AUTOSAR XML (schema 4-3-0)
standard types defined: Boolean, UInt8, SInt8, UInt16, SInt16, UInt32, SInt32, boolean, uint8, sint8, uint16, sint16, uint32, sint32
package /Components
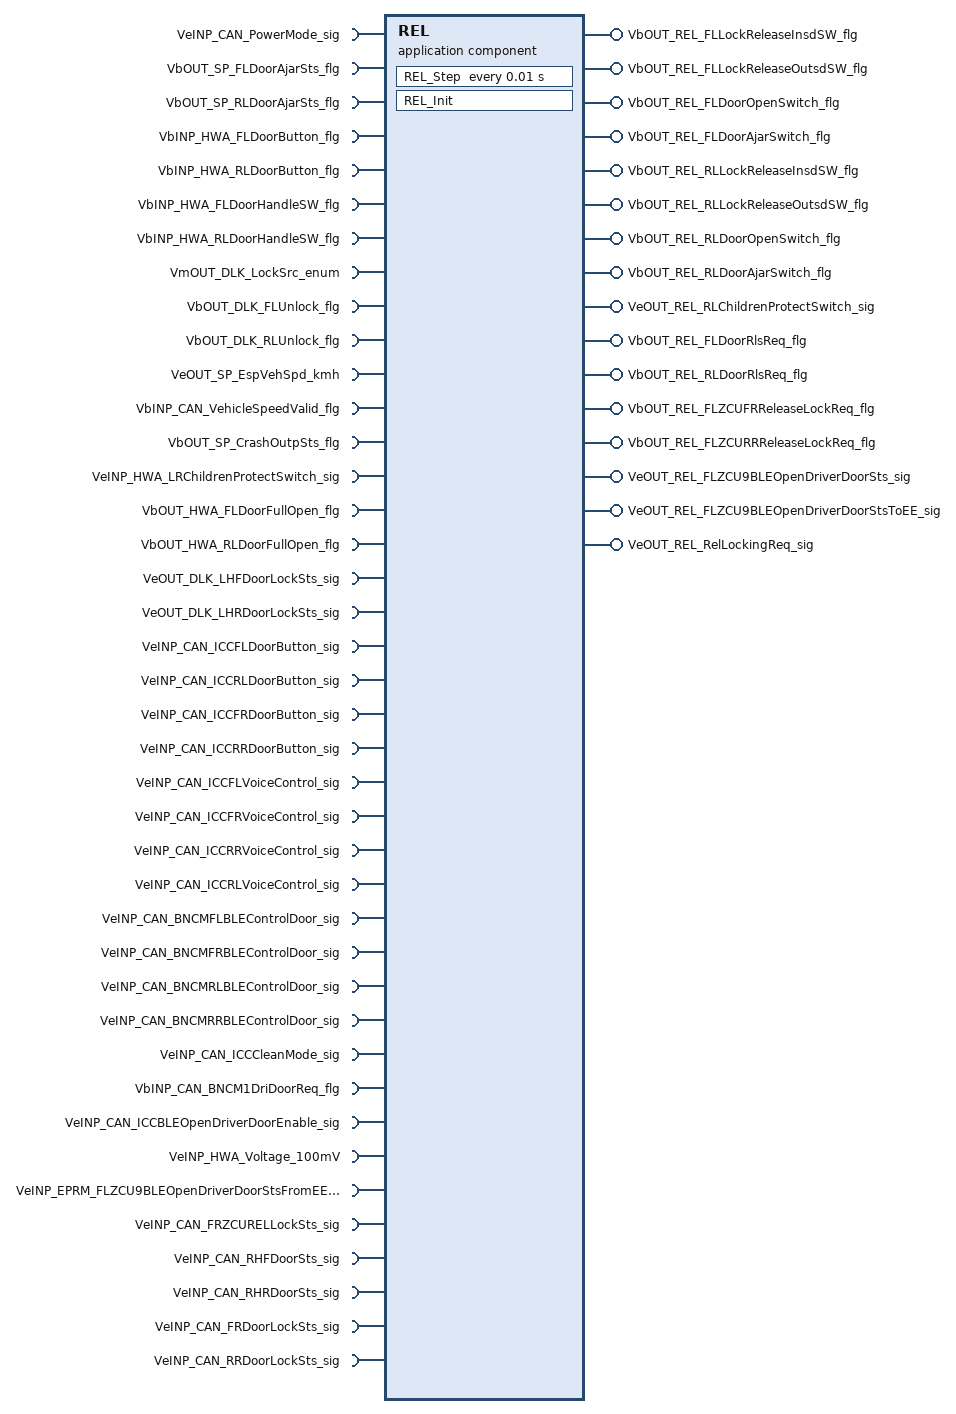
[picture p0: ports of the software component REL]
  application sw component type REL
    40 x require port:
      VeINP_CAN_PowerMode_sig: nonqueued-receiver-com-spec{data-element=VeINP_CAN_PowerMode_sig, init-value=0}, required-interface=VeINP_CAN_PowerMode_sig
      VbOUT_SP_FLDoorAjarSts_flg: nonqueued-receiver-com-spec{data-element=VbOUT_SP_FLDoorAjarSts_flg, init-value=0}, required-interface=VbOUT_SP_FLDoorAjarSts_flg
      VbOUT_SP_RLDoorAjarSts_flg: nonqueued-receiver-com-spec{data-element=VbOUT_SP_RLDoorAjarSts_flg, init-value=0}, required-interface=VbOUT_SP_RLDoorAjarSts_flg
      VbINP_HWA_FLDoorButton_flg: nonqueued-receiver-com-spec{data-element=VbINP_HWA_FLDoorButton_flg, init-value=0}, required-interface=VbINP_HWA_FLDoorButton_flg
      VbINP_HWA_RLDoorButton_flg: nonqueued-receiver-com-spec{data-element=VbINP_HWA_RLDoorButton_flg, init-value=0}, required-interface=VbINP_HWA_RLDoorButton_flg
      VbINP_HWA_FLDoorHandleSW_flg: nonqueued-receiver-com-spec{data-element=VbINP_HWA_FLDoorHandleSW_flg, init-value=0}, required-interface=VbINP_HWA_FLDoorHandleSW_flg
      VbINP_HWA_RLDoorHandleSW_flg: nonqueued-receiver-com-spec{data-element=VbINP_HWA_RLDoorHandleSW_flg, init-value=0}, required-interface=VbINP_HWA_RLDoorHandleSW_flg
      VmOUT_DLK_LockSrc_enum: nonqueued-receiver-com-spec{data-element=VmOUT_DLK_LockSrc_enum, init-value=0}, required-interface=VmOUT_DLK_LockSrc_enum
      VbOUT_DLK_FLUnlock_flg: nonqueued-receiver-com-spec{data-element=VbOUT_DLK_FLUnlock_flg, init-value=0}, required-interface=VbOUT_DLK_FLUnlock_flg
      VbOUT_DLK_RLUnlock_flg: nonqueued-receiver-com-spec{data-element=VbOUT_DLK_RLUnlock_flg, init-value=0}, required-interface=VbOUT_DLK_RLUnlock_flg
      VeOUT_SP_EspVehSpd_kmh: nonqueued-receiver-com-spec{data-element=VeOUT_SP_EspVehSpd_kmh, init-value=0}, required-interface=VeOUT_SP_EspVehSpd_kmh
      VbINP_CAN_VehicleSpeedValid_flg: nonqueued-receiver-com-spec{data-element=VbINP_CAN_VehicleSpeedValid_flg, init-value=0}, required-interface=VbINP_CAN_VehicleSpeedValid_flg
      VbOUT_SP_CrashOutpSts_flg: nonqueued-receiver-com-spec{data-element=VbOUT_SP_CrashOutpSts_flg, init-value=0}, required-interface=VbOUT_SP_CrashOutpSts_flg
      VeINP_HWA_LRChildrenProtectSwitch_sig: nonqueued-receiver-com-spec{data-element=VeINP_HWA_LRChildrenProtectSwitch_sig, init-value=0}, required-interface=VeINP_HWA_LRChildrenProtectSwitch_sig
      VbOUT_HWA_FLDoorFullOpen_flg: nonqueued-receiver-com-spec{data-element=VbOUT_HWA_FLDoorFullOpen_flg, init-value=0}, required-interface=VbOUT_HWA_FLDoorFullOpen_flg
      VbOUT_HWA_RLDoorFullOpen_flg: nonqueued-receiver-com-spec{data-element=VbOUT_HWA_RLDoorFullOpen_flg, init-value=0}, required-interface=VbOUT_HWA_RLDoorFullOpen_flg
      VeOUT_DLK_LHFDoorLockSts_sig: nonqueued-receiver-com-spec{data-element=VeOUT_DLK_LHFDoorLockSts_sig, init-value=0}, required-interface=VeOUT_DLK_LHFDoorLockSts_sig
      VeOUT_DLK_LHRDoorLockSts_sig: nonqueued-receiver-com-spec{data-element=VeOUT_DLK_LHRDoorLockSts_sig, init-value=0}, required-interface=VeOUT_DLK_LHRDoorLockSts_sig
      VeINP_CAN_ICCFLDoorButton_sig: nonqueued-receiver-com-spec{data-element=VeINP_CAN_ICCFLDoorButton_sig, init-value=0}, required-interface=VeINP_CAN_ICCFLDoorButton_sig
      VeINP_CAN_ICCRLDoorButton_sig: nonqueued-receiver-com-spec{data-element=VeINP_CAN_ICCRLDoorButton_sig, init-value=0}, required-interface=VeINP_CAN_ICCRLDoorButton_sig
      VeINP_CAN_ICCFRDoorButton_sig: nonqueued-receiver-com-spec{data-element=VeINP_CAN_ICCFRDoorButton_sig, init-value=0}, required-interface=VeINP_CAN_ICCFRDoorButton_sig
      VeINP_CAN_ICCRRDoorButton_sig: nonqueued-receiver-com-spec{data-element=VeINP_CAN_ICCRRDoorButton_sig, init-value=0}, required-interface=VeINP_CAN_ICCRRDoorButton_sig
      VeINP_CAN_ICCFLVoiceControl_sig: nonqueued-receiver-com-spec{data-element=VeINP_CAN_ICCFLVoiceControl_sig, init-value=0}, required-interface=VeINP_CAN_ICCFLVoiceControl_sig
      VeINP_CAN_ICCFRVoiceControl_sig: nonqueued-receiver-com-spec{data-element=VeINP_CAN_ICCFRVoiceControl_sig, init-value=0}, required-interface=VeINP_CAN_ICCFRVoiceControl_sig
      VeINP_CAN_ICCRRVoiceControl_sig: nonqueued-receiver-com-spec{data-element=VeINP_CAN_ICCRRVoiceControl_sig, init-value=0}, required-interface=VeINP_CAN_ICCRRVoiceControl_sig
      VeINP_CAN_ICCRLVoiceControl_sig: nonqueued-receiver-com-spec{data-element=VeINP_CAN_ICCRLVoiceControl_sig, init-value=0}, required-interface=VeINP_CAN_ICCRLVoiceControl_sig
      VeINP_CAN_BNCMFLBLEControlDoor_sig: nonqueued-receiver-com-spec{data-element=VeINP_CAN_BNCMFLBLEControlDoor_sig, init-value=0}, required-interface=VeINP_CAN_BNCMFLBLEControlDoor_sig
      VeINP_CAN_BNCMFRBLEControlDoor_sig: nonqueued-receiver-com-spec{data-element=VeINP_CAN_BNCMFRBLEControlDoor_sig, init-value=0}, required-interface=VeINP_CAN_BNCMFRBLEControlDoor_sig
      VeINP_CAN_BNCMRLBLEControlDoor_sig: nonqueued-receiver-com-spec{data-element=VeINP_CAN_BNCMRLBLEControlDoor_sig, init-value=0}, required-interface=VeINP_CAN_BNCMRLBLEControlDoor_sig
      VeINP_CAN_BNCMRRBLEControlDoor_sig: nonqueued-receiver-com-spec{data-element=VeINP_CAN_BNCMRRBLEControlDoor_sig, init-value=0}, required-interface=VeINP_CAN_BNCMRRBLEControlDoor_sig
      VeINP_CAN_ICCCleanMode_sig: nonqueued-receiver-com-spec{data-element=VeINP_CAN_ICCCleanMode_sig, init-value=0}, required-interface=VeINP_CAN_ICCCleanMode_sig
      VbINP_CAN_BNCM1DriDoorReq_flg: nonqueued-receiver-com-spec{data-element=VbINP_CAN_BNCM1DriDoorReq_flg, init-value=0}, required-interface=VbINP_CAN_BNCM1DriDoorReq_flg
      VeINP_CAN_ICCBLEOpenDriverDoorEnable_sig: nonqueued-receiver-com-spec{data-element=VeINP_CAN_ICCBLEOpenDriverDoorEnable_sig, init-value=0}, required-interface=VeINP_CAN_ICCBLEOpenDriverDoorEnable_sig
      VeINP_HWA_Voltage_100mV: nonqueued-receiver-com-spec{data-element=VeINP_HWA_Voltage_100mV, init-value=0}, required-interface=VeINP_HWA_Voltage_100mV
      VeINP_EPRM_FLZCU9BLEOpenDriverDoorStsFromEE_sig: nonqueued-receiver-com-spec{data-element=VeINP_EPRM_FLZCU9BLEOpenDriverDoorStsFromEE_sig, init-value=0}, required-interface=VeINP_EPRM_FLZCU9BLEOpenDriverDoorStsFromEE_sig
      VeINP_CAN_FRZCURELLockSts_sig: nonqueued-receiver-com-spec{data-element=VeINP_CAN_FRZCURELLockSts_sig, init-value=0}, required-interface=VeINP_CAN_FRZCURELLockSts_sig
      VeINP_CAN_RHFDoorSts_sig: nonqueued-receiver-com-spec{data-element=VeINP_CAN_RHFDoorSts_sig, init-value=0}, required-interface=VeINP_CAN_RHFDoorSts_sig
      VeINP_CAN_RHRDoorSts_sig: nonqueued-receiver-com-spec{data-element=VeINP_CAN_RHRDoorSts_sig, init-value=0}, required-interface=VeINP_CAN_RHRDoorSts_sig
      VeINP_CAN_FRDoorLockSts_sig: nonqueued-receiver-com-spec{data-element=VeINP_CAN_FRDoorLockSts_sig, init-value=0}, required-interface=VeINP_CAN_FRDoorLockSts_sig
      VeINP_CAN_RRDoorLockSts_sig: nonqueued-receiver-com-spec{data-element=VeINP_CAN_RRDoorLockSts_sig, init-value=0}, required-interface=VeINP_CAN_RRDoorLockSts_sig
    16 x provide port:
      VbOUT_REL_FLLockReleaseInsdSW_flg: nonqueued-sender-com-spec{data-element=VbOUT_REL_FLLockReleaseInsdSW_flg, init-value=0}, provided-interface=VbOUT_REL_FLLockReleaseInsdSW_flg
      VbOUT_REL_FLLockReleaseOutsdSW_flg: nonqueued-sender-com-spec{data-element=VbOUT_REL_FLLockReleaseOutsdSW_flg, init-value=0}, provided-interface=VbOUT_REL_FLLockReleaseOutsdSW_flg
      VbOUT_REL_FLDoorOpenSwitch_flg: nonqueued-sender-com-spec{data-element=VbOUT_REL_FLDoorOpenSwitch_flg, init-value=0}, provided-interface=VbOUT_REL_FLDoorOpenSwitch_flg
      VbOUT_REL_FLDoorAjarSwitch_flg: nonqueued-sender-com-spec{data-element=VbOUT_REL_FLDoorAjarSwitch_flg, init-value=0}, provided-interface=VbOUT_REL_FLDoorAjarSwitch_flg
      VbOUT_REL_RLLockReleaseInsdSW_flg: nonqueued-sender-com-spec{data-element=VbOUT_REL_RLLockReleaseInsdSW_flg, init-value=0}, provided-interface=VbOUT_REL_RLLockReleaseInsdSW_flg
      VbOUT_REL_RLLockReleaseOutsdSW_flg: nonqueued-sender-com-spec{data-element=VbOUT_REL_RLLockReleaseOutsdSW_flg, init-value=0}, provided-interface=VbOUT_REL_RLLockReleaseOutsdSW_flg
      VbOUT_REL_RLDoorOpenSwitch_flg: nonqueued-sender-com-spec{data-element=VbOUT_REL_RLDoorOpenSwitch_flg, init-value=0}, provided-interface=VbOUT_REL_RLDoorOpenSwitch_flg
      VbOUT_REL_RLDoorAjarSwitch_flg: nonqueued-sender-com-spec{data-element=VbOUT_REL_RLDoorAjarSwitch_flg, init-value=0}, provided-interface=VbOUT_REL_RLDoorAjarSwitch_flg
      VeOUT_REL_RLChildrenProtectSwitch_sig: nonqueued-sender-com-spec{data-element=VeOUT_REL_RLChildrenProtectSwitch_sig, init-value=0}, provided-interface=VeOUT_REL_RLChildrenProtectSwitch_sig
      VbOUT_REL_FLDoorRlsReq_flg: nonqueued-sender-com-spec{data-element=VbOUT_REL_FLDoorRlsReq_flg, init-value=0}, provided-interface=VbOUT_REL_FLDoorRlsReq_flg
      VbOUT_REL_RLDoorRlsReq_flg: nonqueued-sender-com-spec{data-element=VbOUT_REL_RLDoorRlsReq_flg, init-value=0}, provided-interface=VbOUT_REL_RLDoorRlsReq_flg
      VbOUT_REL_FLZCUFRReleaseLockReq_flg: nonqueued-sender-com-spec{data-element=VbOUT_REL_FLZCUFRReleaseLockReq_flg, init-value=0}, provided-interface=VbOUT_REL_FLZCUFRReleaseLockReq_flg
      VbOUT_REL_FLZCURRReleaseLockReq_flg: nonqueued-sender-com-spec{data-element=VbOUT_REL_FLZCURRReleaseLockReq_flg, init-value=0}, provided-interface=VbOUT_REL_FLZCURRReleaseLockReq_flg
      VeOUT_REL_FLZCU9BLEOpenDriverDoorSts_sig: nonqueued-sender-com-spec{data-element=VeOUT_REL_FLZCU9BLEOpenDriverDoorSts_sig, init-value=0}, provided-interface=VeOUT_REL_FLZCU9BLEOpenDriverDoorSts_sig
      VeOUT_REL_FLZCU9BLEOpenDriverDoorStsToEE_sig: nonqueued-sender-com-spec{data-element=VeOUT_REL_FLZCU9BLEOpenDriverDoorStsToEE_sig, init-value=0}, provided-interface=VeOUT_REL_FLZCU9BLEOpenDriverDoorStsToEE_sig
      VeOUT_REL_RelLockingReq_sig: nonqueued-sender-com-spec{data-element=VeOUT_REL_RelLockingReq_sig, init-value=0}, provided-interface=VeOUT_REL_RelLockingReq_sig
    behavior REL: data-type-mapping=DataTypeMappingsSet, handle-termination-and-restart=NO-SUPPORT
      init event REL_InitEvent: start-on-event=REL_Init
      timing event Event_Runnable_Step: start-on-event=REL_Step, period=0.01
      runnable REL_Init
      runnable REL_Step
        data-receive-point-by-arguments:
          40 x access:
            IN_VeINP_CAN_PowerMode_sig_VeINP_CAN_PowerMode_sig: accessed-variable=VeINP_CAN_PowerMode_sig.VeINP_CAN_PowerMode_sig
            IN_VbOUT_SP_FLDoorAjarSts_flg_VbOUT_SP_FLDoorAjarSts_flg: accessed-variable=VbOUT_SP_FLDoorAjarSts_flg.VbOUT_SP_FLDoorAjarSts_flg
            IN_VbOUT_SP_RLDoorAjarSts_flg_VbOUT_SP_RLDoorAjarSts_flg: accessed-variable=VbOUT_SP_RLDoorAjarSts_flg.VbOUT_SP_RLDoorAjarSts_flg
            IN_VbINP_HWA_FLDoorButton_flg_VbINP_HWA_FLDoorButton_flg: accessed-variable=VbINP_HWA_FLDoorButton_flg.VbINP_HWA_FLDoorButton_flg
            IN_VbINP_HWA_RLDoorButton_flg_VbINP_HWA_RLDoorButton_flg: accessed-variable=VbINP_HWA_RLDoorButton_flg.VbINP_HWA_RLDoorButton_flg
            IN_VbINP_HWA_FLDoorHandleSW_flg_VbINP_HWA_FLDoorHandleSW_flg: accessed-variable=VbINP_HWA_FLDoorHandleSW_flg.VbINP_HWA_FLDoorHandleSW_flg
            IN_VbINP_HWA_RLDoorHandleSW_flg_VbINP_HWA_RLDoorHandleSW_flg: accessed-variable=VbINP_HWA_RLDoorHandleSW_flg.VbINP_HWA_RLDoorHandleSW_flg
            IN_VmOUT_DLK_LockSrc_enum_VmOUT_DLK_LockSrc_enum: accessed-variable=VmOUT_DLK_LockSrc_enum.VmOUT_DLK_LockSrc_enum
            IN_VbOUT_DLK_FLUnlock_flg_VbOUT_DLK_FLUnlock_flg: accessed-variable=VbOUT_DLK_FLUnlock_flg.VbOUT_DLK_FLUnlock_flg
            IN_VbOUT_DLK_RLUnlock_flg_VbOUT_DLK_RLUnlock_flg: accessed-variable=VbOUT_DLK_RLUnlock_flg.VbOUT_DLK_RLUnlock_flg
            IN_VeOUT_SP_EspVehSpd_kmh_VeOUT_SP_EspVehSpd_kmh: accessed-variable=VeOUT_SP_EspVehSpd_kmh.VeOUT_SP_EspVehSpd_kmh
            IN_VbINP_CAN_VehicleSpeedValid_flg_VbINP_CAN_VehicleSpeedValid_flg: accessed-variable=VbINP_CAN_VehicleSpeedValid_flg.VbINP_CAN_VehicleSpeedValid_flg
            IN_VbOUT_SP_CrashOutpSts_flg_VbOUT_SP_CrashOutpSts_flg: accessed-variable=VbOUT_SP_CrashOutpSts_flg.VbOUT_SP_CrashOutpSts_flg
            IN_VeINP_HWA_LRChildrenProtectSwitch_sig_VeINP_HWA_LRChildrenProtectSwitch_sig: accessed-variable=VeINP_HWA_LRChildrenProtectSwitch_sig.VeINP_HWA_LRChildrenProtectSwitch_sig
            IN_VbOUT_HWA_FLDoorFullOpen_flg_VbOUT_HWA_FLDoorFullOpen_flg: accessed-variable=VbOUT_HWA_FLDoorFullOpen_flg.VbOUT_HWA_FLDoorFullOpen_flg
            IN_VbOUT_HWA_RLDoorFullOpen_flg_VbOUT_HWA_RLDoorFullOpen_flg: accessed-variable=VbOUT_HWA_RLDoorFullOpen_flg.VbOUT_HWA_RLDoorFullOpen_flg
            IN_VeOUT_DLK_LHFDoorLockSts_sig_VeOUT_DLK_LHFDoorLockSts_sig: accessed-variable=VeOUT_DLK_LHFDoorLockSts_sig.VeOUT_DLK_LHFDoorLockSts_sig
            IN_VeOUT_DLK_LHRDoorLockSts_sig_VeOUT_DLK_LHRDoorLockSts_sig: accessed-variable=VeOUT_DLK_LHRDoorLockSts_sig.VeOUT_DLK_LHRDoorLockSts_sig
            IN_VeINP_CAN_ICCFLDoorButton_sig_VeINP_CAN_ICCFLDoorButton_sig: accessed-variable=VeINP_CAN_ICCFLDoorButton_sig.VeINP_CAN_ICCFLDoorButton_sig
            IN_VeINP_CAN_ICCRLDoorButton_sig_VeINP_CAN_ICCRLDoorButton_sig: accessed-variable=VeINP_CAN_ICCRLDoorButton_sig.VeINP_CAN_ICCRLDoorButton_sig
            IN_VeINP_CAN_ICCFRDoorButton_sig_VeINP_CAN_ICCFRDoorButton_sig: accessed-variable=VeINP_CAN_ICCFRDoorButton_sig.VeINP_CAN_ICCFRDoorButton_sig
            IN_VeINP_CAN_ICCRRDoorButton_sig_VeINP_CAN_ICCRRDoorButton_sig: accessed-variable=VeINP_CAN_ICCRRDoorButton_sig.VeINP_CAN_ICCRRDoorButton_sig
            IN_VeINP_CAN_ICCFLVoiceControl_sig_VeINP_CAN_ICCFLVoiceControl_sig: accessed-variable=VeINP_CAN_ICCFLVoiceControl_sig.VeINP_CAN_ICCFLVoiceControl_sig
            IN_VeINP_CAN_ICCFRVoiceControl_sig_VeINP_CAN_ICCFRVoiceControl_sig: accessed-variable=VeINP_CAN_ICCFRVoiceControl_sig.VeINP_CAN_ICCFRVoiceControl_sig
            IN_VeINP_CAN_ICCRRVoiceControl_sig_VeINP_CAN_ICCRRVoiceControl_sig: accessed-variable=VeINP_CAN_ICCRRVoiceControl_sig.VeINP_CAN_ICCRRVoiceControl_sig
            IN_VeINP_CAN_ICCRLVoiceControl_sig_VeINP_CAN_ICCRLVoiceControl_sig: accessed-variable=VeINP_CAN_ICCRLVoiceControl_sig.VeINP_CAN_ICCRLVoiceControl_sig
            IN_VeINP_CAN_BNCMFLBLEControlDoor_sig_VeINP_CAN_BNCMFLBLEControlDoor_sig: accessed-variable=VeINP_CAN_BNCMFLBLEControlDoor_sig.VeINP_CAN_BNCMFLBLEControlDoor_sig
            IN_VeINP_CAN_BNCMFRBLEControlDoor_sig_VeINP_CAN_BNCMFRBLEControlDoor_sig: accessed-variable=VeINP_CAN_BNCMFRBLEControlDoor_sig.VeINP_CAN_BNCMFRBLEControlDoor_sig
            IN_VeINP_CAN_BNCMRLBLEControlDoor_sig_VeINP_CAN_BNCMRLBLEControlDoor_sig: accessed-variable=VeINP_CAN_BNCMRLBLEControlDoor_sig.VeINP_CAN_BNCMRLBLEControlDoor_sig
            IN_VeINP_CAN_BNCMRRBLEControlDoor_sig_VeINP_CAN_BNCMRRBLEControlDoor_sig: accessed-variable=VeINP_CAN_BNCMRRBLEControlDoor_sig.VeINP_CAN_BNCMRRBLEControlDoor_sig
            IN_VeINP_CAN_ICCCleanMode_sig_VeINP_CAN_ICCCleanMode_sig: accessed-variable=VeINP_CAN_ICCCleanMode_sig.VeINP_CAN_ICCCleanMode_sig
            IN_VbINP_CAN_BNCM1DriDoorReq_flg_VbINP_CAN_BNCM1DriDoorReq_flg: accessed-variable=VbINP_CAN_BNCM1DriDoorReq_flg.VbINP_CAN_BNCM1DriDoorReq_flg
            IN_VeINP_CAN_ICCBLEOpenDriverDoorEnable_sig_VeINP_CAN_ICCBLEOpenDriverDoorEnable_sig: accessed-variable=VeINP_CAN_ICCBLEOpenDriverDoorEnable_sig.VeINP_CAN_ICCBLEOpenDriverDoorEnable_sig
            IN_VeINP_HWA_Voltage_100mV_VeINP_HWA_Voltage_100mV: accessed-variable=VeINP_HWA_Voltage_100mV.VeINP_HWA_Voltage_100mV
            IN_VeINP_EPRM_FLZCU9BLEOpenDriverDoorStsFromEE_sig_VeINP_EPRM_FLZCU9BLEOpenDriverDoorStsFromEE_sig: accessed-variable=VeINP_EPRM_FLZCU9BLEOpenDriverDoorStsFromEE_sig.VeINP_EPRM_FLZCU9BLEOpenDriverDoorStsFromEE_sig
            IN_VeINP_CAN_FRZCURELLockSts_sig_VeINP_CAN_FRZCURELLockSts_sig: accessed-variable=VeINP_CAN_FRZCURELLockSts_sig.VeINP_CAN_FRZCURELLockSts_sig
            IN_VeINP_CAN_RHFDoorSts_sig_VeINP_CAN_RHFDoorSts_sig: accessed-variable=VeINP_CAN_RHFDoorSts_sig.VeINP_CAN_RHFDoorSts_sig
            IN_VeINP_CAN_RHRDoorSts_sig_VeINP_CAN_RHRDoorSts_sig: accessed-variable=VeINP_CAN_RHRDoorSts_sig.VeINP_CAN_RHRDoorSts_sig
            IN_VeINP_CAN_FRDoorLockSts_sig_VeINP_CAN_FRDoorLockSts_sig: accessed-variable=VeINP_CAN_FRDoorLockSts_sig.VeINP_CAN_FRDoorLockSts_sig
            IN_VeINP_CAN_RRDoorLockSts_sig_VeINP_CAN_RRDoorLockSts_sig: accessed-variable=VeINP_CAN_RRDoorLockSts_sig.VeINP_CAN_RRDoorLockSts_sig
        data-send-points:
          16 x access:
            OUT_VbOUT_REL_FLLockReleaseInsdSW_flg_VbOUT_REL_FLLockReleaseInsdSW_flg: accessed-variable=VbOUT_REL_FLLockReleaseInsdSW_flg.VbOUT_REL_FLLockReleaseInsdSW_flg
            OUT_VbOUT_REL_FLLockReleaseOutsdSW_flg_VbOUT_REL_FLLockReleaseOutsdSW_flg: accessed-variable=VbOUT_REL_FLLockReleaseOutsdSW_flg.VbOUT_REL_FLLockReleaseOutsdSW_flg
            OUT_VbOUT_REL_FLDoorOpenSwitch_flg_VbOUT_REL_FLDoorOpenSwitch_flg: accessed-variable=VbOUT_REL_FLDoorOpenSwitch_flg.VbOUT_REL_FLDoorOpenSwitch_flg
            OUT_VbOUT_REL_FLDoorAjarSwitch_flg_VbOUT_REL_FLDoorAjarSwitch_flg: accessed-variable=VbOUT_REL_FLDoorAjarSwitch_flg.VbOUT_REL_FLDoorAjarSwitch_flg
            OUT_VbOUT_REL_RLLockReleaseInsdSW_flg_VbOUT_REL_RLLockReleaseInsdSW_flg: accessed-variable=VbOUT_REL_RLLockReleaseInsdSW_flg.VbOUT_REL_RLLockReleaseInsdSW_flg
            OUT_VbOUT_REL_RLLockReleaseOutsdSW_flg_VbOUT_REL_RLLockReleaseOutsdSW_flg: accessed-variable=VbOUT_REL_RLLockReleaseOutsdSW_flg.VbOUT_REL_RLLockReleaseOutsdSW_flg
            OUT_VbOUT_REL_RLDoorOpenSwitch_flg_VbOUT_REL_RLDoorOpenSwitch_flg: accessed-variable=VbOUT_REL_RLDoorOpenSwitch_flg.VbOUT_REL_RLDoorOpenSwitch_flg
            OUT_VbOUT_REL_RLDoorAjarSwitch_flg_VbOUT_REL_RLDoorAjarSwitch_flg: accessed-variable=VbOUT_REL_RLDoorAjarSwitch_flg.VbOUT_REL_RLDoorAjarSwitch_flg
            OUT_VeOUT_REL_RLChildrenProtectSwitch_sig_VeOUT_REL_RLChildrenProtectSwitch_sig: accessed-variable=VeOUT_REL_RLChildrenProtectSwitch_sig.VeOUT_REL_RLChildrenProtectSwitch_sig
            OUT_VbOUT_REL_FLDoorRlsReq_flg_VbOUT_REL_FLDoorRlsReq_flg: accessed-variable=VbOUT_REL_FLDoorRlsReq_flg.VbOUT_REL_FLDoorRlsReq_flg
            OUT_VbOUT_REL_RLDoorRlsReq_flg_VbOUT_REL_RLDoorRlsReq_flg: accessed-variable=VbOUT_REL_RLDoorRlsReq_flg.VbOUT_REL_RLDoorRlsReq_flg
            OUT_VbOUT_REL_FLZCUFRReleaseLockReq_flg_VbOUT_REL_FLZCUFRReleaseLockReq_flg: accessed-variable=VbOUT_REL_FLZCUFRReleaseLockReq_flg.VbOUT_REL_FLZCUFRReleaseLockReq_flg
            OUT_VbOUT_REL_FLZCURRReleaseLockReq_flg_VbOUT_REL_FLZCURRReleaseLockReq_flg: accessed-variable=VbOUT_REL_FLZCURRReleaseLockReq_flg.VbOUT_REL_FLZCURRReleaseLockReq_flg
            OUT_VeOUT_REL_FLZCU9BLEOpenDriverDoorSts_sig_VeOUT_REL_FLZCU9BLEOpenDriverDoorSts_sig: accessed-variable=VeOUT_REL_FLZCU9BLEOpenDriverDoorSts_sig.VeOUT_REL_FLZCU9BLEOpenDriverDoorSts_sig
            OUT_VeOUT_REL_FLZCU9BLEOpenDriverDoorStsToEE_sig_VeOUT_REL_FLZCU9BLEOpenDriverDoorStsToEE_sig: accessed-variable=VeOUT_REL_FLZCU9BLEOpenDriverDoorStsToEE_sig.VeOUT_REL_FLZCU9BLEOpenDriverDoorStsToEE_sig
            OUT_VeOUT_REL_RelLockingReq_sig_VeOUT_REL_RelLockingReq_sig: accessed-variable=VeOUT_REL_RelLockingReq_sig.VeOUT_REL_RelLockingReq_sig
package /Interfaces
  56 x sender receiver interface:
    VeINP_CAN_PowerMode_sig
      data VeINP_CAN_PowerMode_sig: category=VALUE, sw-calibration-access=READ-ONLY, type=UInt8
    VbOUT_SP_FLDoorAjarSts_flg
      data VbOUT_SP_FLDoorAjarSts_flg: category=BOOLEAN, sw-calibration-access=READ-ONLY, type=Boolean
    VbOUT_SP_RLDoorAjarSts_flg
      data VbOUT_SP_RLDoorAjarSts_flg: category=BOOLEAN, sw-calibration-access=READ-ONLY, type=Boolean
    VbINP_HWA_FLDoorButton_flg
      data VbINP_HWA_FLDoorButton_flg: category=BOOLEAN, sw-calibration-access=READ-ONLY, type=Boolean
    VbINP_HWA_RLDoorButton_flg
      data VbINP_HWA_RLDoorButton_flg: category=BOOLEAN, sw-calibration-access=READ-ONLY, type=Boolean
    VbINP_HWA_FLDoorHandleSW_flg
      data VbINP_HWA_FLDoorHandleSW_flg: category=BOOLEAN, sw-calibration-access=READ-ONLY, type=Boolean
    VbINP_HWA_RLDoorHandleSW_flg
      data VbINP_HWA_RLDoorHandleSW_flg: category=BOOLEAN, sw-calibration-access=READ-ONLY, type=Boolean
    VmOUT_DLK_LockSrc_enum
      data VmOUT_DLK_LockSrc_enum: category=VALUE, sw-calibration-access=READ-ONLY, type=UInt8
    VbOUT_DLK_FLUnlock_flg
      data VbOUT_DLK_FLUnlock_flg: category=BOOLEAN, sw-calibration-access=READ-ONLY, type=Boolean
    VbOUT_DLK_RLUnlock_flg
      data VbOUT_DLK_RLUnlock_flg: category=BOOLEAN, sw-calibration-access=READ-ONLY, type=Boolean
    VeOUT_SP_EspVehSpd_kmh
      data VeOUT_SP_EspVehSpd_kmh: category=VALUE, sw-calibration-access=READ-ONLY, type=UInt8
    VbINP_CAN_VehicleSpeedValid_flg
      data VbINP_CAN_VehicleSpeedValid_flg: category=BOOLEAN, sw-calibration-access=READ-ONLY, type=Boolean
    VbOUT_SP_CrashOutpSts_flg
      data VbOUT_SP_CrashOutpSts_flg: category=BOOLEAN, sw-calibration-access=READ-ONLY, type=Boolean
    VeINP_HWA_LRChildrenProtectSwitch_sig
      data VeINP_HWA_LRChildrenProtectSwitch_sig: category=VALUE, sw-calibration-access=READ-ONLY, type=UInt8
    VbOUT_HWA_FLDoorFullOpen_flg
      data VbOUT_HWA_FLDoorFullOpen_flg: category=BOOLEAN, sw-calibration-access=READ-ONLY, type=Boolean
    VbOUT_HWA_RLDoorFullOpen_flg
      data VbOUT_HWA_RLDoorFullOpen_flg: category=BOOLEAN, sw-calibration-access=READ-ONLY, type=Boolean
    VeOUT_DLK_LHFDoorLockSts_sig
      data VeOUT_DLK_LHFDoorLockSts_sig: category=VALUE, sw-calibration-access=READ-ONLY, type=UInt8
    VeOUT_DLK_LHRDoorLockSts_sig
      data VeOUT_DLK_LHRDoorLockSts_sig: category=VALUE, sw-calibration-access=READ-ONLY, type=UInt8
    VeINP_CAN_ICCFLDoorButton_sig
      data VeINP_CAN_ICCFLDoorButton_sig: category=VALUE, sw-calibration-access=READ-ONLY, type=UInt8
    VeINP_CAN_ICCRLDoorButton_sig
      data VeINP_CAN_ICCRLDoorButton_sig: category=VALUE, sw-calibration-access=READ-ONLY, type=UInt8
    VeINP_CAN_ICCFRDoorButton_sig
      data VeINP_CAN_ICCFRDoorButton_sig: category=VALUE, sw-calibration-access=READ-ONLY, type=UInt8
    VeINP_CAN_ICCRRDoorButton_sig
      data VeINP_CAN_ICCRRDoorButton_sig: category=VALUE, sw-calibration-access=READ-ONLY, type=UInt8
    VeINP_CAN_ICCFLVoiceControl_sig
      data VeINP_CAN_ICCFLVoiceControl_sig: category=VALUE, sw-calibration-access=READ-ONLY, type=UInt8
    VeINP_CAN_ICCFRVoiceControl_sig
      data VeINP_CAN_ICCFRVoiceControl_sig: category=VALUE, sw-calibration-access=READ-ONLY, type=UInt8
    VeINP_CAN_ICCRRVoiceControl_sig
      data VeINP_CAN_ICCRRVoiceControl_sig: category=VALUE, sw-calibration-access=READ-ONLY, type=UInt8
    VeINP_CAN_ICCRLVoiceControl_sig
      data VeINP_CAN_ICCRLVoiceControl_sig: category=VALUE, sw-calibration-access=READ-ONLY, type=UInt8
    VeINP_CAN_BNCMFLBLEControlDoor_sig
      data VeINP_CAN_BNCMFLBLEControlDoor_sig: category=VALUE, sw-calibration-access=READ-ONLY, type=UInt8
    VeINP_CAN_BNCMFRBLEControlDoor_sig
      data VeINP_CAN_BNCMFRBLEControlDoor_sig: category=VALUE, sw-calibration-access=READ-ONLY, type=UInt8
    VeINP_CAN_BNCMRLBLEControlDoor_sig
      data VeINP_CAN_BNCMRLBLEControlDoor_sig: category=VALUE, sw-calibration-access=READ-ONLY, type=UInt8
    VeINP_CAN_BNCMRRBLEControlDoor_sig
      data VeINP_CAN_BNCMRRBLEControlDoor_sig: category=VALUE, sw-calibration-access=READ-ONLY, type=UInt8
    VeINP_CAN_ICCCleanMode_sig
      data VeINP_CAN_ICCCleanMode_sig: category=VALUE, sw-calibration-access=READ-ONLY, type=UInt8
    VbINP_CAN_BNCM1DriDoorReq_flg
      data VbINP_CAN_BNCM1DriDoorReq_flg: category=BOOLEAN, sw-calibration-access=READ-ONLY, type=Boolean
    VeINP_CAN_ICCBLEOpenDriverDoorEnable_sig
      data VeINP_CAN_ICCBLEOpenDriverDoorEnable_sig: category=VALUE, sw-calibration-access=READ-ONLY, type=UInt8
    VeINP_HWA_Voltage_100mV
      data VeINP_HWA_Voltage_100mV: category=VALUE, sw-calibration-access=READ-ONLY, type=UInt8
    VeINP_EPRM_FLZCU9BLEOpenDriverDoorStsFromEE_sig
      data VeINP_EPRM_FLZCU9BLEOpenDriverDoorStsFromEE_sig: category=VALUE, sw-calibration-access=READ-ONLY, type=UInt8
    VeINP_CAN_FRZCURELLockSts_sig
      data VeINP_CAN_FRZCURELLockSts_sig: category=VALUE, sw-calibration-access=READ-ONLY, type=UInt8
    VeINP_CAN_RHFDoorSts_sig
      data VeINP_CAN_RHFDoorSts_sig: category=VALUE, sw-calibration-access=READ-ONLY, type=UInt8
    VeINP_CAN_RHRDoorSts_sig
      data VeINP_CAN_RHRDoorSts_sig: category=VALUE, sw-calibration-access=READ-ONLY, type=UInt8
    VeINP_CAN_FRDoorLockSts_sig
      data VeINP_CAN_FRDoorLockSts_sig: category=VALUE, sw-calibration-access=READ-ONLY, type=UInt8
    VeINP_CAN_RRDoorLockSts_sig
      data VeINP_CAN_RRDoorLockSts_sig: category=VALUE, sw-calibration-access=READ-ONLY, type=UInt8
    VbOUT_REL_FLLockReleaseInsdSW_flg
      data VbOUT_REL_FLLockReleaseInsdSW_flg: category=BOOLEAN, sw-calibration-access=READ-ONLY, type=Boolean
    VbOUT_REL_FLLockReleaseOutsdSW_flg
      data VbOUT_REL_FLLockReleaseOutsdSW_flg: category=BOOLEAN, sw-calibration-access=READ-ONLY, type=Boolean
    VbOUT_REL_FLDoorOpenSwitch_flg
      data VbOUT_REL_FLDoorOpenSwitch_flg: category=BOOLEAN, sw-calibration-access=READ-ONLY, type=Boolean
    VbOUT_REL_FLDoorAjarSwitch_flg
      data VbOUT_REL_FLDoorAjarSwitch_flg: category=BOOLEAN, sw-calibration-access=READ-ONLY, type=Boolean
    VbOUT_REL_RLLockReleaseInsdSW_flg
      data VbOUT_REL_RLLockReleaseInsdSW_flg: category=BOOLEAN, sw-calibration-access=READ-ONLY, type=Boolean
    VbOUT_REL_RLLockReleaseOutsdSW_flg
      data VbOUT_REL_RLLockReleaseOutsdSW_flg: category=BOOLEAN, sw-calibration-access=READ-ONLY, type=Boolean
    VbOUT_REL_RLDoorOpenSwitch_flg
      data VbOUT_REL_RLDoorOpenSwitch_flg: category=BOOLEAN, sw-calibration-access=READ-ONLY, type=Boolean
    VbOUT_REL_RLDoorAjarSwitch_flg
      data VbOUT_REL_RLDoorAjarSwitch_flg: category=BOOLEAN, sw-calibration-access=READ-ONLY, type=Boolean
    VeOUT_REL_RLChildrenProtectSwitch_sig
      data VeOUT_REL_RLChildrenProtectSwitch_sig: category=VALUE, sw-calibration-access=READ-ONLY, type=UInt8
    VbOUT_REL_FLDoorRlsReq_flg
      data VbOUT_REL_FLDoorRlsReq_flg: category=BOOLEAN, sw-calibration-access=READ-ONLY, type=Boolean
    VbOUT_REL_RLDoorRlsReq_flg
      data VbOUT_REL_RLDoorRlsReq_flg: category=BOOLEAN, sw-calibration-access=READ-ONLY, type=Boolean
    VbOUT_REL_FLZCUFRReleaseLockReq_flg
      data VbOUT_REL_FLZCUFRReleaseLockReq_flg: category=BOOLEAN, sw-calibration-access=READ-ONLY, type=Boolean
    VbOUT_REL_FLZCURRReleaseLockReq_flg
      data VbOUT_REL_FLZCURRReleaseLockReq_flg: category=BOOLEAN, sw-calibration-access=READ-ONLY, type=Boolean
    VeOUT_REL_FLZCU9BLEOpenDriverDoorSts_sig
      data VeOUT_REL_FLZCU9BLEOpenDriverDoorSts_sig: category=VALUE, sw-calibration-access=READ-ONLY, type=UInt8
    VeOUT_REL_FLZCU9BLEOpenDriverDoorStsToEE_sig
      data VeOUT_REL_FLZCU9BLEOpenDriverDoorStsToEE_sig: category=VALUE, sw-calibration-access=READ-ONLY, type=UInt8
    VeOUT_REL_RelLockingReq_sig
      data VeOUT_REL_RelLockingReq_sig: category=VALUE, sw-calibration-access=READ-ONLY, type=UInt8
package /REL_imp
  swc implementation REL: behavior=REL
    code-descriptors:
      code Default: artifact-descriptors=autosar-engineering-object={short-label=Default, category=SWSRC}
package /DataTypes/SwAddrMethods
  sw addr method CODE: section-type=CODE
  sw addr method CONST: section-type=CONST
  sw addr method VAR: section-type=VAR
package /DataTypes/ApplicationDataTypes
  7 x app type, all with sw-calibration-access=READ-WRITE:
    Boolean: category=BOOLEAN, compu {0=FALSE, 1=TRUE}
    UInt8: category=VALUE, compu {identical}, range phys 0..255
    SInt8: category=VALUE, compu {identical}, range phys -128..127
    UInt16: category=VALUE, compu {identical}, range phys 0..65535
    SInt16: category=VALUE, compu {identical}, range phys -32768..32767
    UInt32: category=VALUE, compu {identical}, range phys 0..4294967295
    SInt32: category=VALUE, compu {identical}, range phys -2147483648..2147483647
  9 x application record data type, all with category=STRUCTURE, sw-calibration-access=READ-WRITE:
    ESC_AngleMotorOut_STRUCT
      4 x application record element:
        LearnSts: category=VALUE, type=UInt8
        CorrectPos_Zero: category=BOOLEAN, type=Boolean
        CorrectPos_Max: category=BOOLEAN, type=Boolean
        ManualCorrectPos: category=VALUE, type=UInt8
    ESC_TelesMotorOut_STRUCT
      4 x application record element:
        LearnSts: category=VALUE, type=UInt8
        CorrectPos_Zero: category=BOOLEAN, type=Boolean
        CorrectPos_Max: category=BOOLEAN, type=Boolean
        ManualCorrectPos: category=VALUE, type=UInt8
    ESC_AngleDebugInfo_STRUCT
      4 x application record element:
        LearnSts: category=VALUE, type=UInt8
        CorrectPos_Zero: category=BOOLEAN, type=Boolean
        CorrectPos_Max: category=BOOLEAN, type=Boolean
        ManualCorrectPos: category=VALUE, type=UInt8
    SteerWheel_TarPosSts_STRUCT
      application record element AngleTarPos: category=VALUE, type=SInt16
      application record element FrontBackTarPos: category=VALUE, type=SInt16
    MIR_EPRMSts_STRUCT
      8 x application record element, all with category=VALUE, type=UInt8:
        L_SaveDrvMode_VtcPos
        L_SaveDrvMode_HrzPos
        L_SaveTiltMode_VtcPos
        L_SaveTiltMode_HrzPos
        R_SaveDrvMode_VtcPos
        R_SaveDrvMode_HrzPos
        R_SaveTiltMode_VtcPos
        R_SaveTiltMode_HrzPos
    MIR_ADJ_STRUCT
      application record element L_Mir_Current_VtcPos: category=VALUE, type=UInt8
      application record element L_Mir_Current_HrzPos: category=VALUE, type=UInt8
    SEAT_DrvOutputs_STRUCT
      4 x application record element:
        LearnSts: category=VALUE, type=UInt8
        CorrectPos_Zero: category=BOOLEAN, type=Boolean
        CorrectPos_Max: category=BOOLEAN, type=Boolean
        ManualCorrectPos: category=VALUE, type=UInt8
    SDU_EPRMTarPosSts_STRUCT
      5 x application record element, all with category=VALUE, type=SInt16:
        HorizTarPos
        VertiTarPos
        BkAnTarPos
        CushTarPos
        LegTarPos
    TURN_DIAG_STRUCT
      5 x application record element:
        OpenLoad: category=BOOLEAN, type=Boolean
        Overload: category=BOOLEAN, type=Boolean
        NormA2D: category=VALUE, type=UInt8
        Turn_LTH: category=VALUE, type=UInt8
        TurnCalib_th: category=VALUE, type=UInt8
  application array data type rt_Array_UInt8_8: category=ARRAY, sw-calibration-access=READ-WRITE
    element rt_Array_UInt8_8: category=VALUE, type=UInt8, array-size-semantics=FIXED-SIZE, max-number-of-elements=8
package /DataTypes/ApplicationDataTypes/DataConstrs
  range DC_ESC_AngleMotorOut_STRUCT: phys 0
  range DC_ESC_TelesMotorOut_STRUCT: phys 0
  range DC_ESC_AngleDebugInfo_STRUCT: phys 0
  range DC_SteerWheel_TarPosSts_STRUCT: phys 0
  range DC_MIR_EPRMSts_STRUCT: phys 0
  range DC_MIR_ADJ_STRUCT: phys 0
  range DC_SEAT_DrvOutputs_STRUCT: phys 0
  range DC_SDU_EPRMTarPosSts_STRUCT: phys 0
  range DC_TURN_DIAG_STRUCT: phys 0
package /DataTypes/ImplementationDataTypes
  10 x impl type:
    ESC_AngleMotorOut_STRUCT: category=STRUCTURE
      4 x element, all with category=TYPE_REFERENCE:
        LearnSts: implementation-data-type=UInt8
        CorrectPos_Zero: implementation-data-type=Boolean
        CorrectPos_Max: implementation-data-type=Boolean
        ManualCorrectPos: implementation-data-type=UInt8
    ESC_TelesMotorOut_STRUCT: category=STRUCTURE
      4 x element, all with category=TYPE_REFERENCE:
        LearnSts: implementation-data-type=UInt8
        CorrectPos_Zero: implementation-data-type=Boolean
        CorrectPos_Max: implementation-data-type=Boolean
        ManualCorrectPos: implementation-data-type=UInt8
    ESC_AngleDebugInfo_STRUCT: category=STRUCTURE
      4 x element, all with category=TYPE_REFERENCE:
        LearnSts: implementation-data-type=UInt8
        CorrectPos_Zero: implementation-data-type=Boolean
        CorrectPos_Max: implementation-data-type=Boolean
        ManualCorrectPos: implementation-data-type=UInt8
    SteerWheel_TarPosSts_STRUCT: category=STRUCTURE
      element AngleTarPos: implementation-data-type=SInt16
      element FrontBackTarPos: implementation-data-type=SInt16
    MIR_EPRMSts_STRUCT: category=STRUCTURE
      8 x element, all with category=TYPE_REFERENCE, implementation-data-type=UInt8:
        L_SaveDrvMode_VtcPos
        L_SaveDrvMode_HrzPos
        L_SaveTiltMode_VtcPos
        L_SaveTiltMode_HrzPos
        R_SaveDrvMode_VtcPos
        R_SaveDrvMode_HrzPos
        R_SaveTiltMode_VtcPos
        R_SaveTiltMode_HrzPos
    MIR_ADJ_STRUCT: category=STRUCTURE
      element L_Mir_Current_VtcPos: implementation-data-type=UInt8
      element L_Mir_Current_HrzPos: implementation-data-type=UInt8
    SEAT_DrvOutputs_STRUCT: category=STRUCTURE
      4 x element, all with category=TYPE_REFERENCE:
        LearnSts: implementation-data-type=UInt8
        CorrectPos_Zero: implementation-data-type=Boolean
        CorrectPos_Max: implementation-data-type=Boolean
        ManualCorrectPos: implementation-data-type=UInt8
    SDU_EPRMTarPosSts_STRUCT: category=STRUCTURE
      5 x element, all with category=TYPE_REFERENCE, implementation-data-type=SInt16:
        HorizTarPos
        VertiTarPos
        BkAnTarPos
        CushTarPos
        LegTarPos
    TURN_DIAG_STRUCT: category=STRUCTURE
      5 x element, all with category=TYPE_REFERENCE:
        OpenLoad: implementation-data-type=Boolean
        Overload: implementation-data-type=Boolean
        NormA2D: implementation-data-type=UInt8
        Turn_LTH: implementation-data-type=UInt8
        TurnCalib_th: implementation-data-type=UInt8
    rt_Array_UInt8_8: category=ARRAY
      element rt_Array_UInt8_8: array-size=8, array-size-semantics=FIXED-SIZE, implementation-data-type=UInt8
package /DataTypes/Units
  unit NoUnit: factor-si-to-unit=1, offset-si-to-unit=0
package /DataTypes/DataTypeMappings
  data type mapping set DataTypeMappingsSet
    data-type-maps:
      application-data-type=Boolean, implementation-data-type=Boolean
      application-data-type=UInt8, implementation-data-type=UInt8
      application-data-type=SInt8, implementation-data-type=SInt8
      application-data-type=UInt16, implementation-data-type=UInt16
      application-data-type=SInt16, implementation-data-type=SInt16
      application-data-type=UInt32, implementation-data-type=UInt32
      application-data-type=SInt32, implementation-data-type=SInt32
      application-data-type=ESC_AngleMotorOut_STRUCT, implementation-data-type=ESC_AngleMotorOut_STRUCT
      application-data-type=ESC_TelesMotorOut_STRUCT, implementation-data-type=ESC_TelesMotorOut_STRUCT
      application-data-type=ESC_AngleDebugInfo_STRUCT, implementation-data-type=ESC_AngleDebugInfo_STRUCT
      application-data-type=SteerWheel_TarPosSts_STRUCT, implementation-data-type=SteerWheel_TarPosSts_STRUCT
      application-data-type=MIR_EPRMSts_STRUCT, implementation-data-type=MIR_EPRMSts_STRUCT
      application-data-type=MIR_ADJ_STRUCT, implementation-data-type=MIR_ADJ_STRUCT
      application-data-type=SEAT_DrvOutputs_STRUCT, implementation-data-type=SEAT_DrvOutputs_STRUCT
      application-data-type=SDU_EPRMTarPosSts_STRUCT, implementation-data-type=SDU_EPRMTarPosSts_STRUCT
      application-data-type=TURN_DIAG_STRUCT, implementation-data-type=TURN_DIAG_STRUCT
      application-data-type=rt_Array_UInt8_8, implementation-data-type=rt_Array_UInt8_8
